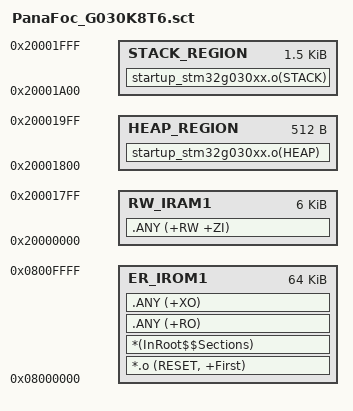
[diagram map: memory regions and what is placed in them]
; *************************************************************
; *** Scatter-Loading Description File generated by uVision ***
; *************************************************************

LR_IROM1 0x08000000 0x00010000
{
  ER_IROM1 0x08000000 0x00010000
  {
    *.o (RESET, +First)
    *(InRoot$$Sections)
    .ANY (+RO)
    .ANY (+XO)
  }

  ;------------------------------------------------------------
  ; RW data + ZI
  ; 0x20000000 ~ 0x200017FF (6KB)
  ;------------------------------------------------------------
  RW_IRAM1 0x20000000 0x00001800
  {
    .ANY (+RW +ZI)
  }

  ;------------------------------------------------------------
  ; Heap (0.5KB)
  ; 0x20001800 ~ 0x200019FF
  ;------------------------------------------------------------
  HEAP_REGION 0x20001800 0x00000200
  {
    startup_stm32g030xx.o(HEAP)
  }

  ;------------------------------------------------------------
  ; Stack (1.5KB)
  ; 0x20001A00 ~ 0x20001FFF
  ; __initial_sp = 0x20002000
  ;------------------------------------------------------------
  STACK_REGION 0x20001A00 0x00000600
  {
    startup_stm32g030xx.o(STACK)
  }
}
